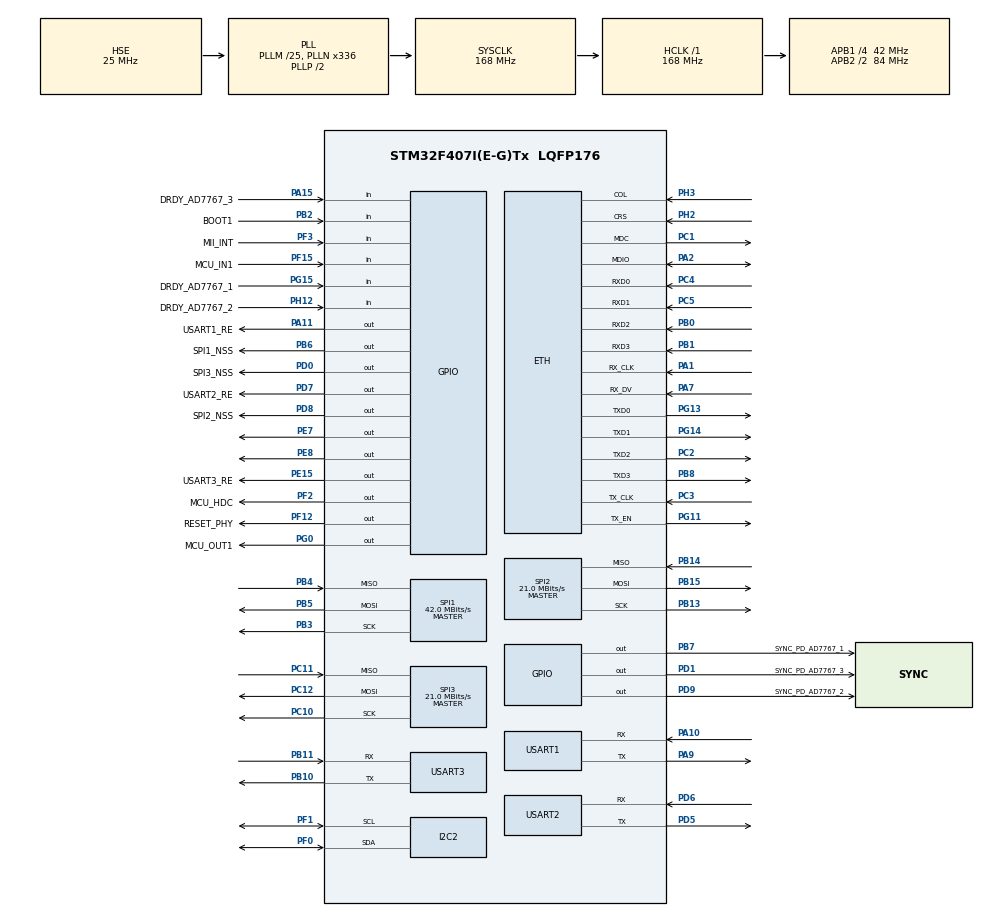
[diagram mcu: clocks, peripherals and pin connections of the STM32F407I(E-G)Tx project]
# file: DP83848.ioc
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ETH.MediaInterface=HAL_ETH_MII_MODE
I2C2.Speed=400000
LWIP.BSP.number=1
LWIP.IP_ADDRESS=172.016.001.069
LWIP.LWIP_DHCP=0
LWIP.NETMASK_ADDRESS=255.255.255.000
LWIP.Version=v2.1.2_Cube
LWIP0.BSP.STBoard=false
LWIP0.BSP.api=BSP_COMPONENT_DRIVER
LWIP0.BSP.component=DP83848
LWIP0.BSP.instance=DP83848
LWIP0.BSP.name=Driver_PHY
LWIP0.BSP.semaphore=S_DP83848
LWIP0.BSP.solution=DP83848
Mcu.Family=STM32F4
Mcu.Name=STM32F407I(E-G)Tx
Mcu.Package=LQFP176
NVIC.PriorityGroup=NVIC_PRIORITYGROUP_4
NVIC.TIM4_IRQn=true\:15\:0\:false\:false\:true\:false\:true\:true
NVIC.TIM7_IRQn=true\:1\:0\:true\:false\:true\:true\:true\:true
NVIC.TimeBase=TIM4_IRQn
NVIC.TimeBaseIP=TIM4
NVIC.USART1_IRQn=true\:2\:0\:true\:false\:true\:true\:true\:true
PA1.Mode=MII
PA1.Signal=ETH_RX_CLK
PA10.Mode=Asynchronous
PA10.Signal=USART1_RX
PA11.GPIO_Label=USART1_RE
PA11.Signal=GPIO_Output
PA13.Mode=Serial_Wire
PA13.Signal=SYS_JTMS-SWDIO
PA14.Mode=Serial_Wire
PA14.Signal=SYS_JTCK-SWCLK
PA15.GPIO_Label=DRDY_AD7767_3
PA15.GPIO_PuPd=GPIO_PULLUP
PA15.Signal=GPIO_Input
PA2.Mode=MII
PA2.Signal=ETH_MDIO
PA7.Mode=MII
PA7.Signal=ETH_RX_DV
PA9.Mode=Asynchronous
PA9.Signal=USART1_TX
PB0.Mode=MII
PB0.Signal=ETH_RXD2
PB1.Mode=MII
PB1.Signal=ETH_RXD3
PB10.Mode=Asynchronous
PB10.Signal=USART3_TX
PB11.Mode=Asynchronous
PB11.Signal=USART3_RX
PB13.Mode=Full_Duplex_Master
PB13.Signal=SPI2_SCK
PB14.Mode=Full_Duplex_Master
PB14.Signal=SPI2_MISO
PB15.Mode=Full_Duplex_Master
PB15.Signal=SPI2_MOSI
PB2.GPIO_Label=BOOT1
PB2.Signal=GPIO_Input
PB3.Mode=Full_Duplex_Master
PB3.Signal=SPI1_SCK
PB4.Mode=Full_Duplex_Master
PB4.Signal=SPI1_MISO
PB5.Mode=Full_Duplex_Master
PB5.Signal=SPI1_MOSI
PB6.GPIO_Label=SPI1_NSS
PB6.Signal=GPIO_Output
PB7.GPIO_Label=SYNC_PD_AD7767_1
PB7.GPIO_PuPd=GPIO_PULLDOWN
PB7.PinState=GPIO_PIN_RESET
PB7.Signal=GPIO_Output
PB8.Mode=MII
PB8.Signal=ETH_TXD3
PC1.Mode=MII
PC1.Signal=ETH_MDC
PC10.Mode=Full_Duplex_Master
PC10.Signal=SPI3_SCK
PC11.Mode=Full_Duplex_Master
PC11.Signal=SPI3_MISO
PC12.Mode=Full_Duplex_Master
PC12.Signal=SPI3_MOSI
PC14-OSC32_IN.Signal=RCC_OSC32_IN
PC15-OSC32_OUT.Signal=RCC_OSC32_OUT
PC2.Mode=MII
PC2.Signal=ETH_TXD2
PC3.Mode=MII
PC3.Signal=ETH_TX_CLK
PC4.Mode=MII
PC4.Signal=ETH_RXD0
PC5.Mode=MII
PC5.Signal=ETH_RXD1
PD0.GPIO_Label=SPI3_NSS
PD0.Signal=GPIO_Output
PD1.GPIO_Label=SYNC_PD_AD7767_3
PD1.GPIO_PuPd=GPIO_PULLDOWN
PD1.PinState=GPIO_PIN_RESET
PD1.Signal=GPIO_Output
PD5.Mode=Asynchronous
PD5.Signal=USART2_TX
PD6.Mode=Asynchronous
PD6.Signal=USART2_RX
PD7.GPIO_Label=USART2_RE
PD7.Signal=GPIO_Output
PD8.GPIO_Label=SPI2_NSS
PD8.Signal=GPIO_Output
PD9.GPIO_Label=SYNC_PD_AD7767_2
PD9.GPIO_PuPd=GPIO_PULLDOWN
PD9.PinState=GPIO_PIN_RESET
PD9.Signal=GPIO_Output
PE15.GPIO_Label=USART3_RE
PE15.Signal=GPIO_Output
PE7.Signal=GPIO_Output
PE8.Signal=GPIO_Output
PF0.Mode=I2C
PF0.Signal=I2C2_SDA
PF1.Mode=I2C
PF1.Signal=I2C2_SCL
PF12.GPIO_Label=RESET_PHY
PF12.PinState=GPIO_PIN_SET
PF12.Signal=GPIO_Output
PF12.Stacked=true
PF15.GPIO_Label=MCU_IN1
PF15.GPIO_PuPd=GPIO_PULLUP
PF15.Signal=GPIO_Input
PF2.GPIO_Label=MCU_HDC
PF2.PinState=GPIO_PIN_RESET
PF2.Signal=GPIO_Output
PF3.GPIO_Label=MII_INT
PF3.GPIO_PuPd=GPIO_PULLUP
PF3.Signal=GPIO_Input
PG0.GPIO_Label=MCU_OUT1
PG0.PinState=GPIO_PIN_RESET
PG0.Signal=GPIO_Output
PG11.Mode=MII
PG11.Signal=ETH_TX_EN
PG13.Mode=MII
PG13.Signal=ETH_TXD0
PG14.Mode=MII
PG14.Signal=ETH_TXD1
PG15.GPIO_Label=DRDY_AD7767_1
PG15.GPIO_PuPd=GPIO_PULLUP
PG15.Signal=GPIO_Input
PH0-OSC_IN.Mode=HSE-External-Oscillator
PH0-OSC_IN.Signal=RCC_OSC_IN
PH1-OSC_OUT.Mode=HSE-External-Oscillator
PH1-OSC_OUT.Signal=RCC_OSC_OUT
PH12.GPIO_Label=DRDY_AD7767_2
PH12.GPIO_PuPd=GPIO_PULLUP
PH12.Signal=GPIO_Input
PH2.Mode=MII
PH2.Signal=ETH_CRS
PH3.Mode=MII
PH3.Signal=ETH_COL
PI10.Signal=ETH_RX_ER
ProjectManager.HeapSize=0x200
ProjectManager.StackSize=0x400
ProjectManager.TargetToolchain=CMake
RCC.48MHZClocksFreq_Value=84000000
RCC.AHBFreq_Value=168000000
RCC.APB1CLKDivider=RCC_HCLK_DIV4
RCC.APB1Freq_Value=42000000
RCC.APB1TimFreq_Value=84000000
RCC.APB2CLKDivider=RCC_HCLK_DIV2
RCC.APB2Freq_Value=84000000
RCC.APB2TimFreq_Value=168000000
RCC.CortexFreq_Value=168000000
RCC.HCLKFreq_Value=168000000
RCC.HSE_VALUE=25000000
RCC.HSI_VALUE=16000000
RCC.LSE_VALUE=32768
RCC.PLLM=25
RCC.PLLN=336
RCC.PLLSourceVirtual=RCC_PLLSOURCE_HSE
RCC.SYSCLKFreq_VALUE=168000000
RCC.SYSCLKSource=RCC_SYSCLKSOURCE_PLLCLK
RCC.VCOOutputFreq_Value=336000000
SPI1.CalculateBaudRate=42.0 MBits/s
SPI1.Direction=SPI_DIRECTION_2LINES
SPI1.Mode=SPI_MODE_MASTER
SPI1.VirtualType=VM_MASTER
SPI2.CalculateBaudRate=21.0 MBits/s
SPI2.Direction=SPI_DIRECTION_2LINES
SPI2.Mode=SPI_MODE_MASTER
SPI2.VirtualType=VM_MASTER
SPI3.CalculateBaudRate=21.0 MBits/s
SPI3.Direction=SPI_DIRECTION_2LINES
SPI3.Mode=SPI_MODE_MASTER
SPI3.VirtualType=VM_MASTER
TIM7.Period=199
TIM7.Prescaler=83
USART1.VirtualMode=VM_ASYNC
USART2.VirtualMode=VM_ASYNC
USART3.VirtualMode=VM_ASYNC
VP_LWIP_VS_Enabled.Mode=Enabled
VP_SYS_VS_tim4.Mode=TIM4
VP_TIM7_VS_ClockSourceINT.Mode=Enable_Timer
board=custom

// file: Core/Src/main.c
/* USER CODE BEGIN Header */
/**
  ******************************************************************************
  * @file           : main.c
  * @brief          : Main program body
  ******************************************************************************
  * @attention
  *
  * Copyright (c) 2026 STMicroelectronics.
  * All rights reserved.
  *
  * This software is licensed under terms that can be found in the LICENSE file
  * in the root directory of this software component.
  * If no LICENSE file comes with this software, it is provided AS-IS.
  *
  ******************************************************************************
  */
/* USER CODE END Header */
#include "main.h"
#include "i2c.h"
#include "lwip.h"
#include "spi.h"
#include "tim.h"
#include "usart.h"
#include "gpio.h"

/* USER CODE BEGIN Includes */
#include "tcp_echoserver.h"
#include "net_config.h"

#include "i2c.h"
/* USER CODE END Includes */

void SystemClock_Config(void);

int main(void)
{

  /* USER CODE BEGIN 1 */

  /*
   * App 链接到 Slot A (0x08010000) 或 Slot B (0x08060000)，
   * 必须在启动时将 VTOR 指向 App 自身的向量表。
   * 使用 GCC 启动文件导出的 g_pfnVectors 符号，
   * 这样编译到哪个槽，VTOR 就自动指向哪个槽。
   */
  extern uint32_t g_pfnVectors[];
  SCB->VTOR = (uint32_t)g_pfnVectors;

  /* Bootloader 在 jump_to_app() 里调用了 __disable_irq() 并停止 SysTick，
   * App 启动后 primask 仍是 1。HAL_Delay / lwIP 计时全部基于 SysTick，
   * 不重新开中断会导致 uwTick 永远是 0，整个 main() 卡死在某个 HAL 延时里。
   * 这里在 VTOR 重定位之后第一时间把全局中断重新打开。 */
  __enable_irq();

  /* USER CODE END 1 */

  /* MCU Configuration--------------------------------------------------------*/

  /* Reset of all peripherals, Initializes the Flash interface and the Systick. */
  HAL_Init();

  /* Configure the system clock */
  SystemClock_Config();

  /* Initialize all configured peripherals */
  MX_GPIO_Init();
  MX_SPI1_Init();
  MX_SPI2_Init();
  MX_SPI3_Init();
  MX_USART1_UART_Init();
  MX_USART2_UART_Init();
  MX_USART3_UART_Init();
  MX_LWIP_Init();
  MX_I2C2_Init();
  MX_TIM7_Init();
  /* USER CODE BEGIN 2 */

  tcp_echoserver_init();
  /* USER CODE END 2 */

  /* Infinite loop */
  while (1)
  {

    /* USER CODE BEGIN 3 */
    MX_LWIP_Process();
    tcp_echoserver_spi_stream_poll();
    net_config_poll();
  }
  /* USER CODE END 3 */
}

void SystemClock_Config(void)
{
  RCC_OscInitTypeDef RCC_OscInitStruct = {0};
  RCC_ClkInitTypeDef RCC_ClkInitStruct = {0};

  /** Configure the main internal regulator output voltage
  */
  __HAL_RCC_PWR_CLK_ENABLE();
  __HAL_PWR_VOLTAGESCALING_CONFIG(PWR_REGULATOR_VOLTAGE_SCALE1);

  /** Initializes the RCC Oscillators according to the specified parameters
  * in the RCC_OscInitTypeDef structure.
  */
  RCC_OscInitStruct.OscillatorType = RCC_OSCILLATORTYPE_HSE;
  RCC_OscInitStruct.HSEState = RCC_HSE_ON;
  RCC_OscInitStruct.PLL.PLLState = RCC_PLL_ON;
  RCC_OscInitStruct.PLL.PLLSource = RCC_PLLSOURCE_HSE;
  RCC_OscInitStruct.PLL.PLLM = 25;
  RCC_OscInitStruct.PLL.PLLN = 336;
  RCC_OscInitStruct.PLL.PLLP = RCC_PLLP_DIV2;
  RCC_OscInitStruct.PLL.PLLQ = 4;
  if (HAL_RCC_OscConfig(&RCC_OscInitStruct) != HAL_OK)
  {
    Error_Handler();
  }

  /** Initializes the CPU, AHB and APB buses clocks
  */
  RCC_ClkInitStruct.ClockType = RCC_CLOCKTYPE_HCLK|RCC_CLOCKTYPE_SYSCLK
                              |RCC_CLOCKTYPE_PCLK1|RCC_CLOCKTYPE_PCLK2;
  RCC_ClkInitStruct.SYSCLKSource = RCC_SYSCLKSOURCE_PLLCLK;
  RCC_ClkInitStruct.AHBCLKDivider = RCC_SYSCLK_DIV1;
  RCC_ClkInitStruct.APB1CLKDivider = RCC_HCLK_DIV4;
  RCC_ClkInitStruct.APB2CLKDivider = RCC_HCLK_DIV2;

  if (HAL_RCC_ClockConfig(&RCC_ClkInitStruct, FLASH_LATENCY_5) != HAL_OK)
  {
    Error_Handler();
  }
}

void HAL_TIM_PeriodElapsedCallback(TIM_HandleTypeDef *htim)
{
  if (htim->Instance == TIM4)
  {
    HAL_IncTick();
  }
  /* USER CODE BEGIN Callback 1 */
  else if (htim->Instance == TIM7)
  {
    /* 200us 采样: 读 3 路 SPI ADC → 5 次平均 → 组帧 (逻辑在 tcp_echoserver.c) */
    tcp_echoserver_tim7_isr();
  }
  /* USER CODE END Callback 1 */
}

void Error_Handler(void)
{
  __disable_irq();
  while (1)
  {
  }
}
